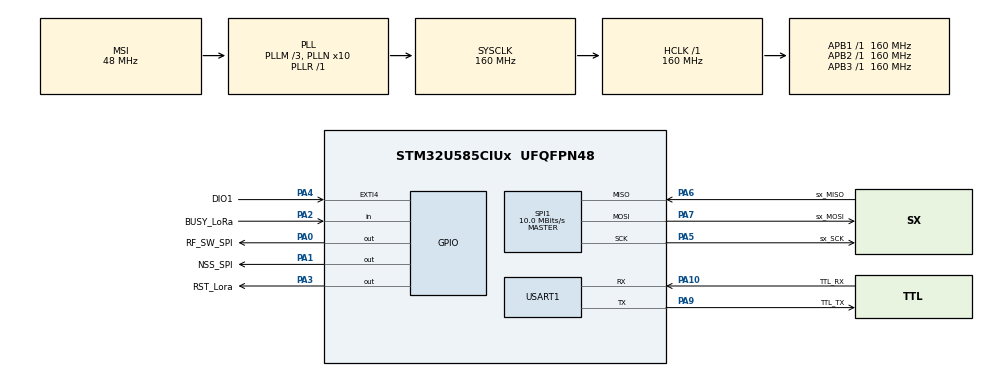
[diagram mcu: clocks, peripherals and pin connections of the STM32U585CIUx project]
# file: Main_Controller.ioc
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CORTEX_M33_NS.userName=CORTEX_M33
Mcu.Family=STM32U5
Mcu.Name=STM32U585CIUx
Mcu.Package=UFQFPN48
NVIC.EXTI4_IRQn=true\:0\:0\:false\:false\:true\:true\:true\:true
NVIC.PriorityGroup=NVIC_PRIORITYGROUP_4
PA0.GPIO_Label=RF_SW_SPI
PA0.Signal=GPIO_Output
PA1.GPIO_Label=NSS_SPI
PA1.PinState=GPIO_PIN_SET
PA1.Signal=GPIO_Output
PA10.GPIO_Label=TTL_RX
PA10.Mode=Asynchronous
PA10.Signal=USART1_RX
PA13\ (JTMS/SWDIO).Signal=DEBUG_JTMS-SWDIO
PA14\ (JTCK/SWCLK).Signal=DEBUG_JTCK-SWCLK
PA15\ (JTDI).GPIO_Label=GPS_RX
PA15\ (JTDI).Signal=USART2_RX
PA2.GPIO_Label=BUSY_LoRa
PA2.Signal=GPIO_Input
PA3.GPIO_Label=RST_Lora
PA3.PinState=GPIO_PIN_SET
PA3.Signal=GPIO_Output
PA4.GPIO_Label=DIO1
PA4.Signal=GPXTI4
PA5.GPIO_Label=sx_SCK
PA5.GPIO_Speed=GPIO_SPEED_FREQ_HIGH
PA5.Mode=Full_Duplex_Master
PA5.Signal=SPI1_SCK
PA6.GPIO_Label=sx_MISO
PA6.GPIO_Speed=GPIO_SPEED_FREQ_HIGH
PA6.Mode=Full_Duplex_Master
PA6.Signal=SPI1_MISO
PA7.GPIO_Label=sx_MOSI
PA7.GPIO_Speed=GPIO_SPEED_FREQ_HIGH
PA7.Mode=Full_Duplex_Master
PA7.Signal=SPI1_MOSI
PA9.GPIO_Label=TTL_TX
PA9.Mode=Asynchronous
PA9.Signal=USART1_TX
ProjectManager.HeapSize=0x200
ProjectManager.StackSize=0x400
ProjectManager.TargetToolchain=STM32CubeIDE
RCC.ADCFreq_Value=16000000
RCC.AHBFreq_Value=160000000
RCC.APB1Freq_Value=160000000
RCC.APB1TimFreq_Value=160000000
RCC.APB2Freq_Value=160000000
RCC.APB2TimFreq_Value=160000000
RCC.APB3Freq_Value=160000000
RCC.CortexFreq_Value=160000000
RCC.EPOD_VALUE=48000000
RCC.HCLKFreq_Value=160000000
RCC.HSE_VALUE=16000000
RCC.HSI48_VALUE=48000000
RCC.HSI_VALUE=16000000
RCC.LSE_VALUE=32768
RCC.LSIDIV_VALUE=32000
RCC.MSIClockRange=RCC_MSIRANGE_0
RCC.MSI_VALUE=48000000
RCC.PLL1R=1
RCC.PLL2FRACN=0
RCC.PLL3FRACN=0
RCC.PLLFRACN=0
RCC.PLLM=3
RCC.PLLN=10
RCC.SYSCLKFreq_VALUE=160000000
RCC.SYSCLKSource=RCC_SYSCLKSOURCE_PLLCLK
RCC.USBFreq_Value=48000000
RCC.VCOOutputFreq_Value=160000000
SPI1.BaudRatePrescaler=SPI_BAUDRATEPRESCALER_16
SPI1.CalculateBaudRate=10.0 MBits/s
SPI1.DataSize=SPI_DATASIZE_8BIT
SPI1.Direction=SPI_DIRECTION_2LINES
SPI1.Mode=SPI_MODE_MASTER
SPI1.VirtualType=VM_MASTER
USART1.VirtualMode-Asynchronous=VM_ASYNC
VP_ICACHE_VS_ICACHE.Mode=DirectMappedCache
VP_LPBAMQUEUE_VS_QUEUE.Mode=QUEUEMODE
VP_LPBAM_VS_SIG1.Mode=SmartRun
VP_LPBAM_VS_SIG4.Mode=LPDMA1
VP_MEMORYMAP_VS_MEMORYMAP.Mode=CurAppReg
VP_PWR_VS_SECSignals.Mode=Security/Privilege
board=custom

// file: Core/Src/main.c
/* USER CODE BEGIN Header */
/**
  ******************************************************************************
  * @file           : main.c
  * @brief          : Main program body
  ******************************************************************************
  * @attention
  *
  * Copyright (c) 2026 STMicroelectronics.
  * All rights reserved.
  *
  * This software is licensed under terms that can be found in the LICENSE file
  * in the root directory of this software component.
  * If no LICENSE file comes with this software, it is provided AS-IS.
  *
  ******************************************************************************
  */
/* USER CODE END Header */
#include "main.h"
#include "icache.h"
#include "spi.h"
#include "usart.h"
#include "gpio.h"

/* USER CODE BEGIN Includes */
#include "sx1262_bringup.h"
/* USER CODE END Includes */

void SystemClock_Config(void);

int main(void)
{

  /* MCU Configuration--------------------------------------------------------*/

  /* Reset of all peripherals, Initializes the Flash interface and the Systick. */
  HAL_Init();

  /* Configure the system clock */
  SystemClock_Config();

  /* Initialize all configured peripherals */
  MX_GPIO_Init();
  MX_SPI1_Init();
  MX_USART1_UART_Init();
  MX_ICACHE_Init();
  /* USER CODE BEGIN 2 */
  ( void ) sx1262_bringup_run();
  /* USER CODE END 2 */

  /* Infinite loop */
  while (1)
  {

  }
}

void SystemClock_Config(void)
{
  RCC_OscInitTypeDef RCC_OscInitStruct = {0};
  RCC_ClkInitTypeDef RCC_ClkInitStruct = {0};

  /** Configure the main internal regulator output voltage
  */
  if (HAL_PWREx_ControlVoltageScaling(PWR_REGULATOR_VOLTAGE_SCALE1) != HAL_OK)
  {
    Error_Handler();
  }

  /** Initializes the CPU, AHB and APB buses clocks
  */
  RCC_OscInitStruct.OscillatorType = RCC_OSCILLATORTYPE_MSI;
  RCC_OscInitStruct.MSIState = RCC_MSI_ON;
  RCC_OscInitStruct.MSICalibrationValue = RCC_MSICALIBRATION_DEFAULT;
  RCC_OscInitStruct.MSIClockRange = RCC_MSIRANGE_0;
  RCC_OscInitStruct.PLL.PLLState = RCC_PLL_ON;
  RCC_OscInitStruct.PLL.PLLSource = RCC_PLLSOURCE_MSI;
  RCC_OscInitStruct.PLL.PLLMBOOST = RCC_PLLMBOOST_DIV4;
  RCC_OscInitStruct.PLL.PLLM = 3;
  RCC_OscInitStruct.PLL.PLLN = 10;
  RCC_OscInitStruct.PLL.PLLP = 2;
  RCC_OscInitStruct.PLL.PLLQ = 2;
  RCC_OscInitStruct.PLL.PLLR = 1;
  RCC_OscInitStruct.PLL.PLLRGE = RCC_PLLVCIRANGE_1;
  RCC_OscInitStruct.PLL.PLLFRACN = 0;
  if (HAL_RCC_OscConfig(&RCC_OscInitStruct) != HAL_OK)
  {
    Error_Handler();
  }

  /** Initializes the CPU, AHB and APB buses clocks
  */
  RCC_ClkInitStruct.ClockType = RCC_CLOCKTYPE_HCLK|RCC_CLOCKTYPE_SYSCLK
                              |RCC_CLOCKTYPE_PCLK1|RCC_CLOCKTYPE_PCLK2
                              |RCC_CLOCKTYPE_PCLK3;
  RCC_ClkInitStruct.SYSCLKSource = RCC_SYSCLKSOURCE_PLLCLK;
  RCC_ClkInitStruct.AHBCLKDivider = RCC_SYSCLK_DIV1;
  RCC_ClkInitStruct.APB1CLKDivider = RCC_HCLK_DIV1;
  RCC_ClkInitStruct.APB2CLKDivider = RCC_HCLK_DIV1;
  RCC_ClkInitStruct.APB3CLKDivider = RCC_HCLK_DIV1;

  if (HAL_RCC_ClockConfig(&RCC_ClkInitStruct, FLASH_LATENCY_4) != HAL_OK)
  {
    Error_Handler();
  }
}

void Error_Handler(void)
{
  __disable_irq();
  while (1)
  {
  }
}
